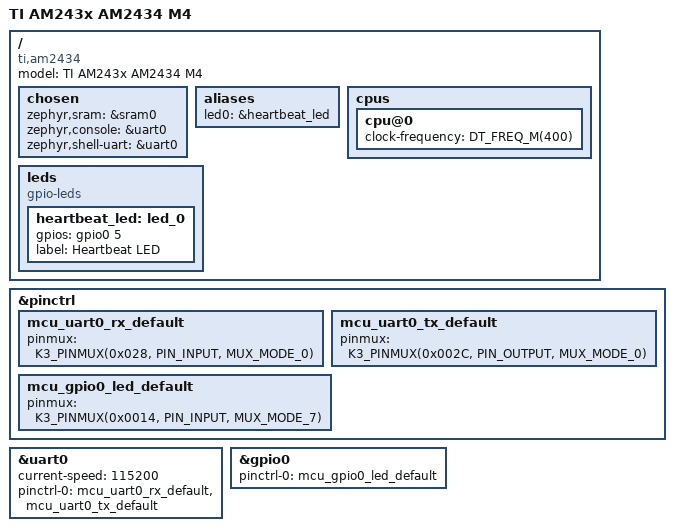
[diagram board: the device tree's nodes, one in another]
/*
 * Copyright (c) 2025 Texas Instruments Incorporated
 *
 * SPDX-License-Identifier: Apache-2.0
 */

/dts-v1/;

#include <ti/am64x_am243x_m4.dtsi>

/ {
	model = "TI AM243x AM2434 M4";
	compatible = "ti,am2434";

	chosen {
	 zephyr,sram = &sram0;
	 zephyr,console = &uart0;
	 zephyr,shell-uart = &uart0;
	};
 
	aliases {
		led0 = &heartbeat_led;
	};

	cpus {
		cpu@0 {
			status = "okay";
			clock-frequency = <DT_FREQ_M(400)>;
		};
	};

	leds: leds {
		compatible = "gpio-leds";
		heartbeat_led: led_0 {
			gpios = <&gpio0 5 GPIO_ACTIVE_HIGH>;
			label = "Heartbeat LED";
		};
	};
};

&pinctrl {
	mcu_uart0_rx_default: mcu_uart0_rx_default {
		pinmux = <K3_PINMUX(0x028, PIN_INPUT, MUX_MODE_0)>;
	};
	mcu_uart0_tx_default: mcu_uart0_tx_default {
		pinmux = <K3_PINMUX(0x002C, PIN_OUTPUT, MUX_MODE_0)>;
	};
	mcu_gpio0_led_default: mcu_gpio0_led_default {
		pinmux = <K3_PINMUX(0x0014, PIN_INPUT, MUX_MODE_7)>;
	};
};

 &uart0 {
	current-speed = <115200>;
	pinctrl-0 = <&mcu_uart0_rx_default &mcu_uart0_tx_default>;
	pinctrl-names = "default";
	status = "okay";
};

&gpio0 {
	pinctrl-0 = <&mcu_gpio0_led_default>;
	pinctrl-names = "default";
	status = "okay";
};
